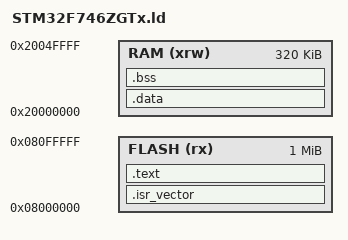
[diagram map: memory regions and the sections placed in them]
/* Linker script for STM32F746ZG (1 MB Flash, 320 KB RAM) */

ENTRY(Reset_Handler)

MEMORY
{
  FLASH (rx)  : ORIGIN = 0x08000000, LENGTH = 1024K
  RAM   (xrw) : ORIGIN = 0x20000000, LENGTH = 320K
}

SECTIONS
{
  .isr_vector :
  {
    . = ALIGN(4);
    KEEP(*(.isr_vector))
    . = ALIGN(4);
  } >FLASH

  .text :
  {
    . = ALIGN(4);
    *(.text*)
    *(.rodata*)
    KEEP(*(.init))
    KEEP(*(.fini))
    . = ALIGN(4);
  } >FLASH

  .data : AT (ADDR(.text) + SIZEOF(.text))
  {
    . = ALIGN(4);
    _sdata = .;
    *(.data*)
    . = ALIGN(4);
    _edata = .;
  } >RAM

  .bss :
  {
    . = ALIGN(4);
    _sbss = .;
    *(.bss*)
    *(COMMON)
    . = ALIGN(4);
    _ebss = .;
  } >RAM

  _sidata = LOADADDR(.data);
}
